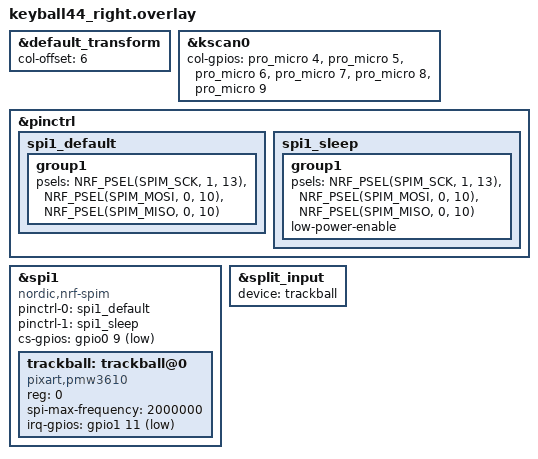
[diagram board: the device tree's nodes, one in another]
/*
 * Copyright (c) 2020 ZMK Contributors
 *
 * SPDX-License-Identifier: MIT
 */

#include "keyball44.dtsi"
#include "keyball44_trackball_split.dtsi"

&default_transform {
    col-offset = <6>;
};

/* No &nice_view_spi CS override here on purpose. ZMK's own
 * nice_view_adapter/boards/nice_nano_v2.overlay already sets
 * cs-gpios = <&pro_micro 1 GPIO_ACTIVE_HIGH> -- the identical value -- so the
 * override this config used to carry was always a no-op. It also cannot live
 * in a shield overlay: shield overlays are concatenated in SHIELD order, so
 * `nice_view_spi` is not defined yet when this file is read (it comes from the
 * adapter, listed after us). It used to work only because it sat in the
 * keymap, which Zephyr applies last.
 */

&kscan0 {
	col-gpios
		= <&pro_micro 4 GPIO_ACTIVE_HIGH>
		, <&pro_micro 5 GPIO_ACTIVE_HIGH>
		, <&pro_micro 6 GPIO_ACTIVE_HIGH>
		, <&pro_micro 7 GPIO_ACTIVE_HIGH>
		, <&pro_micro 8 GPIO_ACTIVE_HIGH>
        , <&pro_micro 9 GPIO_ACTIVE_HIGH>
		;
};

&pinctrl {
    spi1_default: spi1_default {
        group1 {
            psels = <NRF_PSEL(SPIM_SCK, 1, 13)>,
                <NRF_PSEL(SPIM_MOSI, 0, 10)>,
                <NRF_PSEL(SPIM_MISO, 0, 10)>;
        };
    };

    spi1_sleep: spi1_sleep {
        group1 {
            psels = <NRF_PSEL(SPIM_SCK, 1, 13)>,
                <NRF_PSEL(SPIM_MOSI, 0, 10)>,
                <NRF_PSEL(SPIM_MISO, 0, 10)>;
            low-power-enable;
        };
    };
};

&spi1 {
    status = "okay";
    compatible = "nordic,nrf-spim";
    pinctrl-0 = <&spi1_default>;
    pinctrl-1 = <&spi1_sleep>;
    pinctrl-names = "default", "sleep";
    cs-gpios = <&gpio0 9 GPIO_ACTIVE_LOW>;

    trackball: trackball@0 {
        status = "okay";
        compatible = "pixart,pmw3610";
        reg = <0>;
        spi-max-frequency = <2000000>;
        irq-gpios = <&gpio1 11 (GPIO_ACTIVE_LOW | GPIO_PULL_UP)>;
        /* scroll-layers/snipe-layers REMOVED: the driver implements those by
         * reading the active layer, which only exists on the central. This half
         * is now a peripheral, so it just forwards raw motion; scroll/snipe are
         * re-created on the dongle via layer-gated input-processors. */
    };
};

/* Forward this half's trackball to the dongle. The listener stays disabled here
 * (defined in keyball44_trackball_split.dtsi); only the dongle enables it. */
&split_input {
    device = <&trackball>;
};
